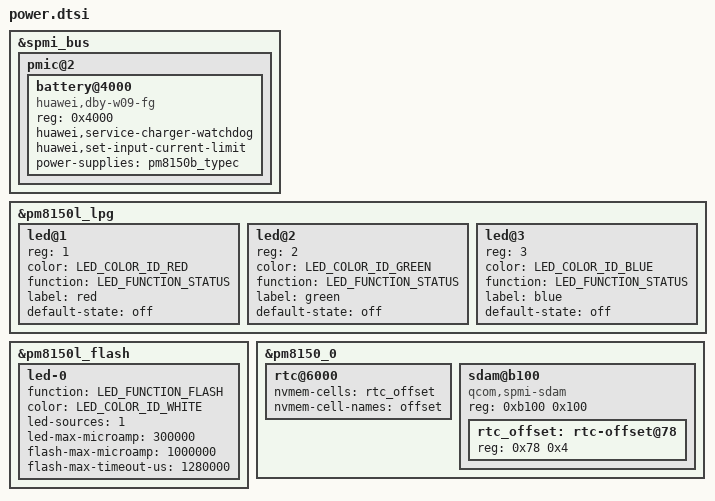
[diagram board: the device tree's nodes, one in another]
// SPDX-License-Identifier: BSD-3-Clause
#include <dt-bindings/leds/common.h>

&spmi_bus {
	pmic@2 {
		battery@4000 {
			compatible = "huawei,dby-w09-fg";
			reg = <0x4000>;
			huawei,service-charger-watchdog;
			/* the USB input limit follows the USB-C supply (TCPM) */
			huawei,set-input-current-limit;
			power-supplies = <&pm8150b_typec>;
		};
	};
};

&pm8150l_lpg {
	status = "okay";
	led@1 {
		reg = <1>;
		color = <LED_COLOR_ID_RED>;
		function = LED_FUNCTION_STATUS;
		label = "red";
		default-state = "off";
	};
	led@2 {
		reg = <2>;
		color = <LED_COLOR_ID_GREEN>;
		function = LED_FUNCTION_STATUS;
		label = "green";
		default-state = "off";
	};
	led@3 {
		reg = <3>;
		color = <LED_COLOR_ID_BLUE>;
		function = LED_FUNCTION_STATUS;
		label = "blue";
		default-state = "off";
	};
};

/* Rear camera flash: one white LED on channel 1 of the PM8150L flash block
 * (stock: torch_0/flash_0 behind switch_0, 300 mA torch, 1 A flash, 1.28 s). */
&pm8150l_flash {
	status = "okay";
	led-0 {
		function = LED_FUNCTION_FLASH;
		color = <LED_COLOR_ID_WHITE>;
		led-sources = <1>;
		led-max-microamp = <300000>;
		flash-max-microamp = <1000000>;
		flash-max-timeout-us = <1280000>;
	};
};

/* RTC: the PM8150's RTC block reads fine on its own, but RTC_SET_TIME is
 * refused with -ENODEV unless rtc-pm8xxx has an nvmem cell to keep the
 * offset between the raw counter and the epoch (pm8xxx_rtc_update_offset()
 * returns -ENODEV when it has neither an nvmem cell nor the UEFI fallback,
 * and a tablet that boots through ABL has no EFI variables).
 *
 * The PM8150 offers scratch memory for exactly that in SDAM 0xb100, and
 * HarmonyOS uses it itself (qcom,pm8150@0/sdam@b100 in the stock DTBO).
 * Nothing else in mainline binds that address on this platform, so it is
 * free: the offset survives a reboot in PMIC scratch memory, which is what
 * the driver expects.
 */
&pm8150_0 {
	rtc@6000 {
		nvmem-cells = <&rtc_offset>;
		nvmem-cell-names = "offset";
	};

	sdam@b100 {
		compatible = "qcom,spmi-sdam";
		reg = <0xb100 0x100>;
		#address-cells = <1>;
		#size-cells = <1>;
		ranges = <0 0xb100 0x100>;

		rtc_offset: rtc-offset@78 {
			reg = <0x78 0x4>;
		};
	};
};
